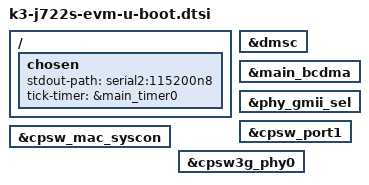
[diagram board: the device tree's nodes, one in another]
// SPDX-License-Identifier: GPL-2.0
/*
 * Common J722S EVM dts file for SPLs
 * Copyright (C) 2024 Texas Instruments Incorporated - https://www.ti.com/
 */

#include "k3-j722s-binman.dtsi"

/ {
	chosen {
		stdout-path = "serial2:115200n8";
		tick-timer = &main_timer0;
	};
};

&dmsc {
	bootph-pre-ram;
};

&main_bcdma {
	bootph-pre-ram;
};

&phy_gmii_sel {
	bootph-all;
};

&cpsw_port1 {
	bootph-all;
};

&cpsw_mac_syscon {
	bootph-all;
};

&cpsw3g_phy0 {
	bootph-all;
};
